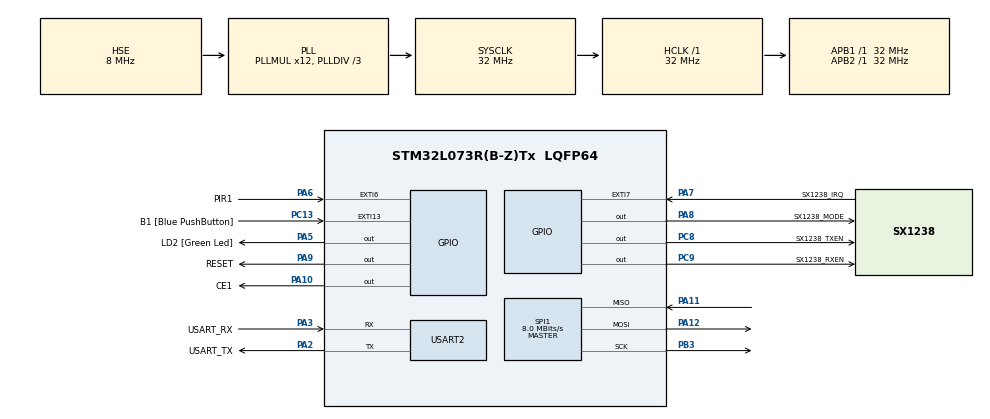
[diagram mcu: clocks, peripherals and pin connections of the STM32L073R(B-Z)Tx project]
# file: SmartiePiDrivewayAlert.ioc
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Mcu.Family=STM32L0
Mcu.Name=STM32L073R(B-Z)Tx
Mcu.Package=LQFP64
NVIC.EXTI4_15_IRQn=true\:0\:0\:false\:false\:true\:true
PA10.GPIO_Label=CE1
PA10.Signal=GPIO_Output
PA11.Mode=Full_Duplex_Master
PA11.Signal=SPI1_MISO
PA12.Mode=Full_Duplex_Master
PA12.Signal=SPI1_MOSI
PA13.GPIO_Label=TMS
PA13.Mode=Serial_Wire
PA13.Signal=SYS_SWDIO
PA14.GPIO_Label=TCK
PA14.Mode=Serial_Wire
PA14.Signal=SYS_SWCLK
PA2.GPIO_Label=USART_TX
PA2.Mode=Asynchronous
PA2.Signal=USART2_TX
PA3.GPIO_Label=USART_RX
PA3.Mode=Asynchronous
PA3.Signal=USART2_RX
PA5.GPIO_Label=LD2 [Green Led]
PA5.Signal=GPIO_Output
PA6.GPIO_Label=PIR1
PA6.Signal=GPXTI6
PA7.GPIO_Label=SX1238_IRQ
PA7.Signal=GPXTI7
PA8.GPIO_Label=SX1238_MODE
PA8.Signal=GPIO_Output
PA9.GPIO_Label=RESET
PA9.Signal=GPIO_Output
PB3.Mode=Full_Duplex_Master
PB3.Signal=SPI1_SCK
PC13.GPIO_Label=B1 [Blue PushButton]
PC13.GPIO_ModeDefaultEXTI=GPIO_MODE_IT_RISING
PC13.Signal=GPXTI13
PC14-OSC32_IN.Mode=LSE-External-Oscillator
PC14-OSC32_IN.Signal=RCC_OSC32_IN
PC15-OSC32_OUT.Mode=LSE-External-Oscillator
PC15-OSC32_OUT.Signal=RCC_OSC32_OUT
PC8.GPIO_Label=SX1238_TXEN
PC8.Signal=GPIO_Output
PC9.GPIO_Label=SX1238_RXEN
PC9.Signal=GPIO_Output
PH0-OSC_IN.GPIO_Label=MCO
PH0-OSC_IN.Mode=HSE-External-Clock-Source
PH0-OSC_IN.Signal=RCC_OSC_IN
ProjectManager.HeapSize=0x200
ProjectManager.StackSize=0x400
ProjectManager.TargetToolchain=TrueSTUDIO
RCC.AHBFreq_Value=32000000
RCC.APB1Freq_Value=32000000
RCC.APB1TimFreq_Value=32000000
RCC.APB2Freq_Value=32000000
RCC.APB2TimFreq_Value=32000000
RCC.HCLKFreq_Value=32000000
RCC.HSE_VALUE=8000000
RCC.HSI16_VALUE=16000000
RCC.HSI48_VALUE=48000000
RCC.HSI_VALUE=16000000
RCC.MSI_VALUE=2097000
RCC.PLLDIV=RCC_PLLDIV_3
RCC.PLLMUL=RCC_PLLMUL_12
RCC.PLLSourceVirtual=RCC_PLLSOURCE_HSE
RCC.SYSCLKFreq_VALUE=32000000
RCC.SYSCLKSource=RCC_SYSCLKSOURCE_PLLCLK
RCC.VCOOutputFreq_Value=96000000
SPI1.BaudRatePrescaler=SPI_BAUDRATEPRESCALER_4
SPI1.CalculateBaudRate=8.0 MBits/s
SPI1.Direction=SPI_DIRECTION_2LINES
SPI1.Mode=SPI_MODE_MASTER
SPI1.VirtualType=VM_MASTER
USART2.VirtualMode-Asynchronous=VM_ASYNC
board=NUCLEO-L073RZ

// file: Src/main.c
/**
 ******************************************************************************
 * @file           : main.c
 * @brief          : Main program body
 ******************************************************************************
 ** This notice applies to any and all portions of this file
 * that are not between comment pairs USER CODE BEGIN and
 * USER CODE END. Other portions of this file, whether
 * inserted by the user or by software development tools
 * are owned by their respective copyright owners.
 *
 * COPYRIGHT(c) 2018 STMicroelectronics
 *
 * Redistribution and use in source and binary forms, with or without modification,
 * are permitted provided that the following conditions are met:
 *   1. Redistributions of source code must retain the above copyright notice,
 *      this list of conditions and the following disclaimer.
 *   2. Redistributions in binary form must reproduce the above copyright notice,
 *      this list of conditions and the following disclaimer in the documentation
 *      and/or other materials provided with the distribution.
 *   3. Neither the name of STMicroelectronics nor the names of its contributors
 *      may be used to endorse or promote products derived from this software
 *      without specific prior written permission.
 *
 * THIS SOFTWARE IS PROVIDED BY THE COPYRIGHT HOLDERS AND CONTRIBUTORS "AS IS"
 * AND ANY EXPRESS OR IMPLIED WARRANTIES, INCLUDING, BUT NOT LIMITED TO, THE
 * IMPLIED WARRANTIES OF MERCHANTABILITY AND FITNESS FOR A PARTICULAR PURPOSE ARE
 * DISCLAIMED. IN NO EVENT SHALL THE COPYRIGHT HOLDER OR CONTRIBUTORS BE LIABLE
 * FOR ANY DIRECT, INDIRECT, INCIDENTAL, SPECIAL, EXEMPLARY, OR CONSEQUENTIAL
 * DAMAGES (INCLUDING, BUT NOT LIMITED TO, PROCUREMENT OF SUBSTITUTE GOODS OR
 * SERVICES; LOSS OF USE, DATA, OR PROFITS; OR BUSINESS INTERRUPTION) HOWEVER
 * CAUSED AND ON ANY THEORY OF LIABILITY, WHETHER IN CONTRACT, STRICT LIABILITY,
 * OR TORT (INCLUDING NEGLIGENCE OR OTHERWISE) ARISING IN ANY WAY OUT OF THE USE
 * OF THIS SOFTWARE, EVEN IF ADVISED OF THE POSSIBILITY OF SUCH DAMAGE.
 *
 ******************************************************************************
 */
#include "main.h"
#include "stm32l0xx_hal.h"
#include "spi.h"
#include "usart.h"
#include "gpio.h"

/* USER CODE BEGIN Includes */
#include "string.h"
#include "SX1238/SX1238_STM32_Driver.h"
/* USER CODE END Includes */

/* USER CODE BEGIN PV */
/* Private variables ---------------------------------------------------------*/
int16_t packetnum = 0;  // packet counter, we increment per xmission
/* USER CODE END PV */

void SystemClock_Config(void);

/* USER CODE BEGIN PFP */
/* Private function prototypes -----------------------------------------------*/

/* USER CODE END PFP */

/* USER CODE BEGIN 0 */

//uint8_t spiDataRcv;
//uint8_t regVal = 0x24;
/* USER CODE END 0 */

int main(void)
{

	/* MCU Configuration----------------------------------------------------------*/

	/* Reset of all peripherals, Initializes the Flash interface and the Systick. */
	HAL_Init();

	/* Configure the system clock */
	SystemClock_Config();

	/* Initialize all configured peripherals */
	MX_GPIO_Init();
	MX_USART2_UART_Init();
	MX_SPI1_Init();
	/* USER CODE BEGIN 2 */

	SX1238_Init(); //Initialize SX1238 Trx

	/* USER CODE END 2 */

	/* Infinite loop */
	while (1)
	{

	}

}

void SystemClock_Config(void)
{

	RCC_OscInitTypeDef RCC_OscInitStruct;
	RCC_ClkInitTypeDef RCC_ClkInitStruct;
	RCC_PeriphCLKInitTypeDef PeriphClkInit;

	/**Configure the main internal regulator output voltage
	 */
	__HAL_PWR_VOLTAGESCALING_CONFIG(PWR_REGULATOR_VOLTAGE_SCALE1);

	/**Initializes the CPU, AHB and APB busses clocks
	 */
	RCC_OscInitStruct.OscillatorType = RCC_OSCILLATORTYPE_HSE;
	RCC_OscInitStruct.HSEState = RCC_HSE_BYPASS;
	RCC_OscInitStruct.PLL.PLLState = RCC_PLL_ON;
	RCC_OscInitStruct.PLL.PLLSource = RCC_PLLSOURCE_HSE;
	RCC_OscInitStruct.PLL.PLLMUL = RCC_PLLMUL_12;
	RCC_OscInitStruct.PLL.PLLDIV = RCC_PLLDIV_3;
	if (HAL_RCC_OscConfig(&RCC_OscInitStruct) != HAL_OK)
	{
		_Error_Handler(__FILE__, __LINE__);
	}

	/**Initializes the CPU, AHB and APB busses clocks
	 */
	RCC_ClkInitStruct.ClockType = RCC_CLOCKTYPE_HCLK|RCC_CLOCKTYPE_SYSCLK
			|RCC_CLOCKTYPE_PCLK1|RCC_CLOCKTYPE_PCLK2;
	RCC_ClkInitStruct.SYSCLKSource = RCC_SYSCLKSOURCE_PLLCLK;
	RCC_ClkInitStruct.AHBCLKDivider = RCC_SYSCLK_DIV1;
	RCC_ClkInitStruct.APB1CLKDivider = RCC_HCLK_DIV1;
	RCC_ClkInitStruct.APB2CLKDivider = RCC_HCLK_DIV1;

	if (HAL_RCC_ClockConfig(&RCC_ClkInitStruct, FLASH_LATENCY_1) != HAL_OK)
	{
		_Error_Handler(__FILE__, __LINE__);
	}

	PeriphClkInit.PeriphClockSelection = RCC_PERIPHCLK_USART2;
	PeriphClkInit.Usart2ClockSelection = RCC_USART2CLKSOURCE_PCLK1;
	if (HAL_RCCEx_PeriphCLKConfig(&PeriphClkInit) != HAL_OK)
	{
		_Error_Handler(__FILE__, __LINE__);
	}

	/**Configure the Systick interrupt time
	 */
	HAL_SYSTICK_Config(HAL_RCC_GetHCLKFreq()/1000);

	/**Configure the Systick
	 */
	HAL_SYSTICK_CLKSourceConfig(SYSTICK_CLKSOURCE_HCLK);

	/* SysTick_IRQn interrupt configuration */
	HAL_NVIC_SetPriority(SysTick_IRQn, 0, 0);
}

/* USER CODE BEGIN 4 */

/**
 * @brief EXTI line detection callbacks
 * @param GPIO_Pin: Specifies the pins connected EXTI line
 * @retval None
 */
void HAL_GPIO_EXTI_Callback(uint16_t GPIO_Pin)
{
	if (GPIO_Pin == PIR1_Pin)//if from motion sensor
	{
		char radiopacket[25] = "Driveway Alarm Triggered!";

		//transmit packets
		SX1238_Send_Frame(NODE_TO_ADDR, radiopacket, strlen(radiopacket), false, false);

		//char *msg = "Driveway Alarm Triggered!\n\r";

		//HAL_UART_Transmit(&huart2, (uint8_t*)msg, strlen(msg), 0xFFFF);
	}else if(GPIO_Pin == SX1238_IRQ_Pin)//if from trx
	{
		//let SX1238 driver handle from here
		SX1238_Handle_Interrupt();
	}
}

/* USER CODE END 4 */

void _Error_Handler(char *file, int line)
{
	while(1)
	{
	}
}

/************************ (C) COPYRIGHT STMicroelectronics *****END OF FILE****/
